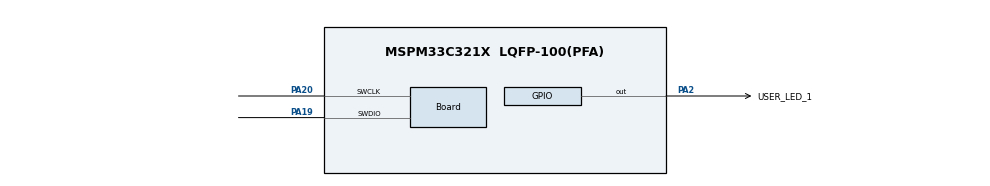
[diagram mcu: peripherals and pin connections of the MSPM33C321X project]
/**
 * @cliArgs --device "MSPM33C321X" --part "Default" --package "LQFP-100(PFA)" --product "mspm33_sdk@1.00.00.00"
 * @versions {"tool":"1.25.0+4268"}
 */

/**
 * Import the modules used in this configuration.
 */
const GPIO  = scripting.addModule("/ti/driverlib/GPIO", {}, false);
const GPIO1 = GPIO.addInstance();
const SPI   = scripting.addModule("/ti/driverlib/SPI", {}, false);
const SPI1  = SPI.addInstance();

/**
 * Write custom configuration values to the imported modules.
 */
GPIO1.$name                               = "GPIO_LEDS";
GPIO1.associatedPins[0].$name             = "USER_LED_1";
GPIO1.associatedPins[0].launchPadShortcut = "LED2BlueEn";
GPIO1.associatedPins[0].pin.$assign       = "PA2";

const Board                       = scripting.addModule("/ti/driverlib/Board", {}, false);
Board.peripheral.$assign          = "DEBUGSS";
Board.peripheral.swclkPin.$assign = "PA20";
Board.peripheral.swdioPin.$assign = "PA19";

SPI1.$name               = "SPI_0";
SPI1.sclkPinConfig.$name = "ti_driverlib_gpio_GPIOPinGeneric0";
SPI1.mosiPinConfig.$name = "ti_driverlib_gpio_GPIOPinGeneric1";
SPI1.misoPinConfig.$name = "ti_driverlib_gpio_GPIOPinGeneric2";
SPI1.cs0PinConfig.$name  = "ti_driverlib_gpio_GPIOPinGeneric3";

const SYSCTL              = scripting.addModule("/ti/driverlib/SYSCTL", {}, false);
SYSCTL.peripheral.$assign = "SYSCTL";

const ProjectConfig              = scripting.addModule("/ti/project_config/ProjectConfig", {}, false);
ProjectConfig.migrationCondition = true;

/**
 * Pinmux solution for unlocked pins/peripherals. This ensures that minor changes to the automatic solver in a future
 * version of the tool will not impact the pinmux you originally saw.  These lines can be completely deleted in order to
 * re-solve from scratch.
 */
SPI1.peripheral.$suggestSolution         = "UC2";
SPI1.peripheral.sclkPin.$suggestSolution = "PA11";
SPI1.peripheral.mosiPin.$suggestSolution = "PA5";
SPI1.peripheral.misoPin.$suggestSolution = "PA10";
SPI1.peripheral.cs0Pin.$suggestSolution  = "PC2";
